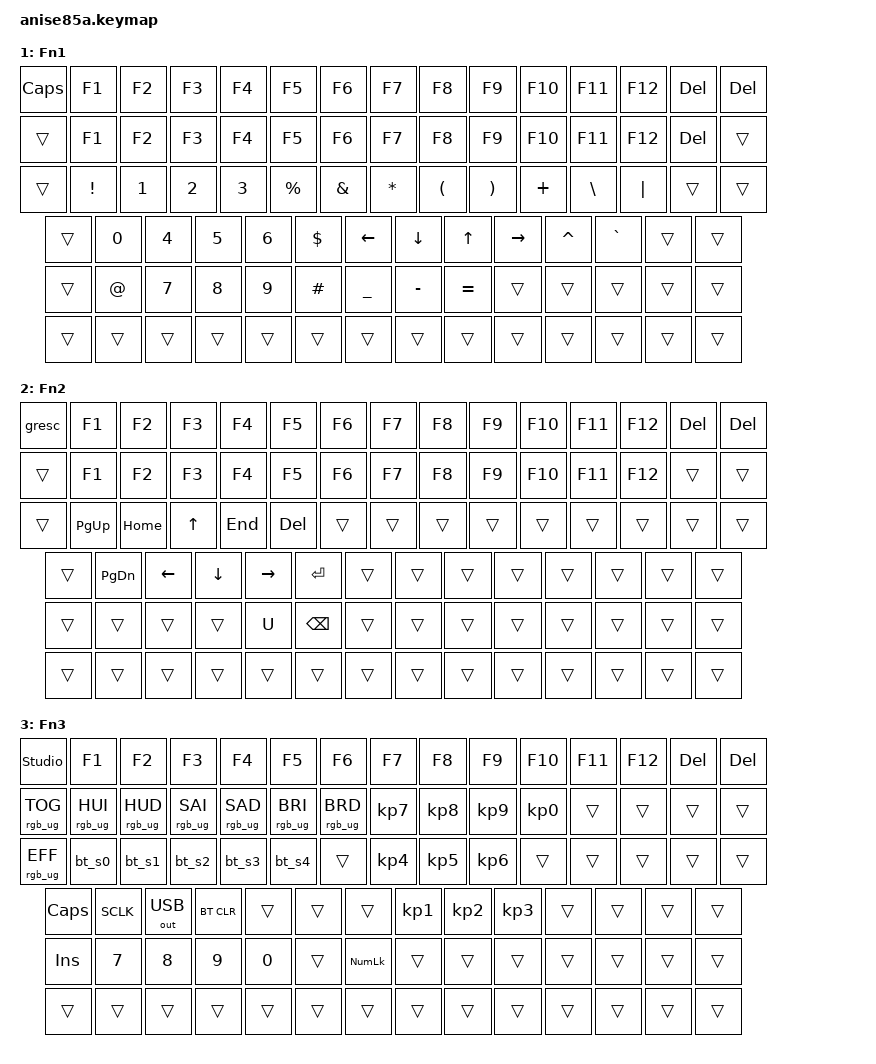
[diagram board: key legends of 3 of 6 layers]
/*
 * Copyright (c) 2020 The ZMK Contributors
 *
 * SPDX-License-Identifier: MIT
 */

#include <behaviors.dtsi>
#include <dt-bindings/zmk/rgb.h>
#include <dt-bindings/zmk/bt.h>
#include <dt-bindings/zmk/outputs.h>
#include <dt-bindings/zmk/keys.h>

/ {
    behaviors {
        gresc: grave_escape {
            compatible = "zmk,behavior-mod-morph";
            label = "GRAVE_ESCAPE";
            #binding-cells = <0>;
            bindings = <&kp ESC>, <&kp GRAVE>;
            mods = <(MOD_LGUI|MOD_LSFT|MOD_RGUI|MOD_RSFT)>;
        };
    };
    macros {
        bt_s0: bt_s0 {
            label = "bt_s0";
            compatible = "zmk,behavior-macro";
            #binding-cells = <0>;
            bindings = <&macro_tap &out OUT_BLE &bt BT_SEL 0>;
        };
        bt_s1: bt_s1 {
            label = "bt_s1";
            compatible = "zmk,behavior-macro";
            #binding-cells = <0>;
            bindings = <&macro_tap &out OUT_BLE &bt BT_SEL 1>;
        };
        bt_s2: bt_s2 {
            label = "bt_s2";
            compatible = "zmk,behavior-macro";
            #binding-cells = <0>;
            bindings = <&macro_tap &out OUT_BLE &bt BT_SEL 2>;
        };
        bt_s3: bt_s3 {
            label = "bt_s3";
            compatible = "zmk,behavior-macro";
            #binding-cells = <0>;
            bindings = <&macro_tap &out OUT_BLE &bt BT_SEL 3>;
        };
        bt_s4: bt_s4 {
            label = "bt_s4";
            compatible = "zmk,behavior-macro";
            #binding-cells = <0>;
            bindings = <&macro_tap &out OUT_BLE &bt BT_SEL 4>;
        };
    };
    keymap {
        compatible = "zmk,keymap";

// -------------------------------------------       ------------------------------------------------------
// | ESC | |  1   |  2  |  3   |  4  | | 5   |       |  6  | | 7 |  8  |  9  | 10  | 11  | 12  |
// | GESC |  1  |  2  |  3  |  4  |  5  |  6 |       |  7  |  8  |  9  |  0  |  -  |  =  |   BKSPC | | HOME  |
// | TAB   |  Q   |  W  |  E   |  R  |  T  |        |  Y  |  U  |  I  |  O  |  P  |  [  |  ]  |  \ | | END   |
// | CAPS   |  A   |  S  |  D   |  F  |  G  |        |  H  |  J  |  K  |  L  |  ;  |  '  |   ENTER | | PGUP  |
// | SHIFT   |  Z   |  X  |  C   |  V   |  B  |       |  N  |  M  |  ,  |  .  |  /   |  RSHFT  || UP|| PGDN  |
// | F | LCTL | LGUI | LALT |    SPACE  | FN2 |       |   SPACE   | FN1  | RALT |  RCTL  | LEFT | DN | RIGHT |
// -------------------------------------------        ------------------------------------------------------

        // 0
        default_layer {
            display-name = "Base";
            bindings = <
    &kp ESC   &kp F1   &kp F2   &kp F3   &kp F4  &kp F5  &kp F6 /**/   &kp F7  &kp F8     &kp F9 &kp F10 &kp F11 &kp F12        &kp DEL                          &kp C_PP
    &kp GRAVE &kp N1   &kp N2   &kp N3   &kp N4   &kp N5  &kp N6 /**/   &kp N7    &kp N8   &kp N9    &kp N0    &kp MINUS &kp EQUAL &kp BSPC                       &kp HOME
    &kp TAB    &kp Q    &kp W    &kp E    &kp R    &kp T        /**/ &kp Y     &kp U    &kp I     &kp O     &kp P     &kp LBKT  &kp RBKT &kp BSPC                &kp END
    &kp ESC      &kp A    &kp S    &kp D    &kp F  &kp G         /**/  &kp H     &kp J    &kp K     &kp L     &kp SEMI  &kp SQT   &kp RET                         &kp PG_UP
    &kp LSHFT     &kp Z    &kp X    &kp C    &kp V  &kp B       /**/    &kp N     &kp M    &kp COMMA &kp DOT   &kp FSLH  &kp RSHFT                   &kp UP      &kp PG_DN
    &kp LCTRL &mo 3 &kp LGUI  &kp LALT  &kp SPACE     &mo 2    /**/ &kp SPACE &mo 1    &mo 4      &mo 5                             &kp LEFT        &kp DOWN   &kp RIGHT 
            >;
        };
        // 1
        fn_layer {
            display-name = "Fn1";
            bindings = <
    &kp CAPS  &kp F1   &kp F2   &kp F3   &kp F4  &kp F5  &kp F6 /**/   &kp F7  &kp F8     &kp F9 &kp F10 &kp F11 &kp F12        &kp DEL                          &kp DEL
    &trans     &kp F1     &kp F2   &kp F3    &kp F4   &kp F5    &kp F6   /**/   &kp F7   &kp F8   &kp F9   &kp F10   &kp F11 &kp F12     &kp DEL                        &trans
    &trans      &kp EXCL   &kp N1   &kp N2    &kp N3   &kp PRCNT         /**/ &kp AMPS  &kp STAR &kp LPAR &kp RPAR  &kp PLUS  &kp BSLH  &kp PIPE  &trans                &trans
    &trans       &kp N0     &kp N4   &kp N5    &kp N6   &kp DLLR         /**/  &kp LEFT  &kp DOWN &kp UP   &kp RIGHT &kp CARET  &kp GRAVE  &trans                       &trans
    &trans         &kp AT     &kp N7   &kp N8    &kp N9   &kp HASH       /**/    &kp UNDER &kp MINUS &kp EQUAL &trans  &trans  &trans                         &trans    &trans
    &trans  &trans    &trans      &trans             &trans      &trans  /**/    &trans        &trans &trans &trans  &trans                         &trans    &trans   &trans
            >;
        };
        // 2
        fn2_layer {
            display-name = "Fn2";
            bindings = <
    &gresc    &kp F1   &kp F2   &kp F3   &kp F4  &kp F5  &kp F6 /**/   &kp F7  &kp F8     &kp F9 &kp F10 &kp F11 &kp F12        &kp DEL                          &kp DEL
    &trans     &kp F1       &kp F2       &kp F3       &kp F4    &kp F5    &kp F6   /**/   &kp F7    &kp F8    &kp F9    &kp F10    &kp F11 &kp F12 &trans               &trans
    &trans      &kp PG_UP &kp HOME   &kp UP      &kp END      &kp DEL              /**/ &trans &trans    &trans    &trans     &trans  &trans  &trans &trans             &trans
    &trans        &kp PG_DN  &kp LEFT     &kp DOWN     &kp RIGHT &kp RET         /**/  &trans &trans    &trans    &trans     &trans  &trans  &trans                     &trans
    &trans           &trans       &trans      &trans       &kp U      &kp BSPC     /**/     &trans     &trans &trans &trans  &trans  &trans                   &trans    &trans
    &trans  &trans    &trans      &trans             &trans      &trans  /**/    &trans        &trans &trans &trans  &trans                         &trans    &trans   &trans
            >;
        };
        // 3
        kbd_func_layer {
            display-name = "Fn3";
            bindings = <
    &studio_unlock  &kp F1   &kp F2   &kp F3   &kp F4  &kp F5  &kp F6 /**/   &kp F7  &kp F8     &kp F9 &kp F10 &kp F11 &kp F12        &kp DEL                          &kp DEL
    &rgb_ug RGB_TOG &rgb_ug RGB_HUI  &rgb_ug RGB_HUD &rgb_ug RGB_SAI &rgb_ug RGB_SAD &rgb_ug RGB_BRI &rgb_ug RGB_BRD  /**/   &kp KP_N7 &kp KP_N8 &kp KP_N9 &kp KP_N0  &trans  &trans  &trans                     &trans
    &rgb_ug RGB_EFF &bt_s0   &bt_s1     &bt_s2       &bt_s3       &bt_s4                                              /**/ &trans &kp KP_N4 &kp KP_N5 &kp KP_N6  &trans  &trans  &trans &trans                   &trans
    &kp CAPS      &kp SCLK      &out OUT_USB &bt BT_CLR   &trans    &trans                                            /**/  &trans &kp KP_N1 &kp KP_N2 &kp KP_N3  &trans  &trans  &trans                         &trans
    &kp INS        &kp N7         &kp N8      &kp N9       &kp N0     &trans                                          /**/     &kp KP_NUM &trans &trans &trans  &trans  &trans                         &trans    &trans
    &trans  &trans    &trans      &trans             &trans      &trans                                               /**/    &trans        &trans &trans &trans  &trans                     &trans    &trans   &trans
            >;
        };
        // 4 -- keyd [sym], held on right Alt
        sym_layer {
            display-name = "Sym";
            bindings = <
    &trans &trans &trans &trans &trans &trans &trans &trans &trans &trans &trans &trans &trans &trans &trans
    &trans &trans &trans &trans &trans &trans &trans &trans &trans &trans &trans &trans &trans &trans &trans
    &kp EQUAL  &kp EXCL &kp N1   &kp N2   &kp N3   &kp PRCNT    /**/ &kp AMPS  &kp STAR &kp LPAR  &kp RPAR  &kp PLUS  &kp BSLH  &kp PIPE &kp DEL                 &trans
    &kp CAPS     &kp N0   &kp N4   &kp N5   &kp N6 &kp DLLR     /**/  &kp LEFT  &kp DOWN &kp UP    &kp RIGHT &kp CARET &kp GRAVE &trans                          &trans
    &trans        &kp AT   &kp N7   &kp N8   &kp N9 &kp HASH    /**/    &kp MINUS &kp HOME &kp PG_UP &kp PG_DN &kp END   &trans                      &trans      &trans
    &trans &trans &trans &trans &trans &trans &trans &trans &trans &trans &trans &trans &trans
            >;
        };
        // 5 -- keyd [fn], held on right Ctrl
        fkey_layer {
            display-name = "FKeys";
            bindings = <
    &trans &trans &trans &trans &trans &trans &trans &trans &trans &trans &trans &trans &trans &trans &trans
    &trans &trans &trans &trans &trans &trans &trans &trans &trans &trans &trans &trans &trans &trans &trans
    &trans     &trans   &kp F1   &kp F2   &kp F3   &trans       /**/ &trans    &trans   &trans    &trans    &trans    &kp F11   &kp F12  &trans                  &trans
    &trans       &kp F10  &kp F4   &kp F5   &kp F6 &trans       /**/  &trans    &trans   &trans    &trans    &trans    &trans    &trans                          &trans
    &trans        &trans   &kp F7   &kp F8   &kp F9 &trans      /**/    &trans    &trans   &trans    &trans    &trans    &trans                      &trans      &trans
    &trans &trans &trans &trans &trans &trans &trans &trans &trans &trans &trans &trans &trans
            >;
        };
    };
};

    // &trans          &trans           &trans          &trans          &trans          &trans          &trans           /**/   &kp KP_N7 &kp KP_N8 &kp KP_N9 &kp KP_N0  &trans  &trans  &trans                     &trans
//         // 0
//         default_layer {
//             bindings = <
//     &gresc   &kp N1   &kp N2   &kp N3   &kp N4   &kp N5  &kp N6 /**/   &kp N7    &kp N8   &kp N9    &kp N0    &kp MINUS &kp EQUAL &kp BSPC
//     &kp TAB    &kp Q    &kp W    &kp E    &kp R    &kp T        /**/ &kp Y     &kp U    &kp I     &kp O     &kp P     &kp LBKT  &kp RBKT &kp BSPC
//     &kp ESC     &kp A    &kp S    &kp D    &kp F  &kp G         /**/  &kp H     &kp J    &kp K     &kp L     &kp SEMI  &kp SQT   &kp RET
//     &kp LSHFT     &kp Z    &kp X    &kp C    &kp V  &kp B       /**/    &kp N     &kp M    &kp COMMA &kp DOT   &kp FSLH  &kp RSHFT
//     &kp LALT    &kp LGUI  &kp LCTRL      &kp SPACE     &mo 2    /**/ &kp SPACE &mo 1    &kp RALT  &kp K_APP  &kp RCTRL
//             >;
//         };
//         // 1
//         fn_layer {
//             bindings = <
//     &trans     &kp F1     &kp F2   &kp F3    &kp F4   &kp F5    &kp F6   /**/   &kp F7   &kp F8   &kp F9   &kp F10   &kp F11 &kp F12     &kp DEL
//     &trans      &kp EXCL   &kp N1   &kp N2    &kp N3   &kp PRCNT         /**/ &kp AMPS  &kp STAR &kp LPAR &kp RPAR  &kp PLUS  &kp BSLH  &kp PIPE  &trans
//     &trans       &kp N0     &kp N4   &kp N5    &kp N6   &kp DLLR         /**/  &kp LEFT  &kp DOWN &kp UP   &kp RIGHT &kp CARET  &kp GRAVE  &trans
//     &trans         &kp AT     &kp N7   &kp N8    &kp N9   &kp HASH       /**/    &kp UNDER &kp MINUS &kp EQUAL &trans  &trans  &kp PG_UP
//     &trans            &trans      &trans             &trans      &trans  /**/    &trans        &trans &trans &trans  &kp PG_DN
//             >;
//         };

//         // 0
//         default_layer {
//             bindings = <
//     &gresc   &kp N1   &kp N2   &kp N3   &kp N4   &kp N5  &kp N6 /**/   &kp N7    &kp N8   &kp N9    &kp N0    &kp MINUS &kp EQUAL &kp BSPC
//     &kp TAB    &kp Q    &kp W    &kp E    &kp R    &kp T        /**/ &kp Y     &kp U    &kp I     &kp O     &kp P     &kp LBKT  &kp RBKT &kp BSLH
//     &kp CAPS     &kp A    &kp S    &kp D    &kp F  &kp G        /**/  &kp H     &kp J    &kp K     &kp L     &kp SEMI  &kp SQT   &kp RET
//     &kp LSHFT     &kp Z    &kp X    &kp C    &kp V  &kp B       /**/    &kp N     &kp M    &kp COMMA &kp DOT   &kp FSLH  &kp RSHFT
//     &kp LCTRL    &kp LGUI  &kp LALT      &kp SPACE     &mo 2    /**/ &kp SPACE &mo 1    &kp RALT  &kp K_APP  &kp RCTRL
//             >;
//         };
//         // 1
//         fn_layer {
//             bindings = <
//     &trans     &kp F1     &kp F2   &kp F3    &kp F4   &kp F5    &kp F6   /**/   &kp F7   &kp F8   &kp F9   &kp F10   &kp F11 &kp F12     &kp DEL
//     &trans      &trans     &kp N1   &kp N2    &kp N3   &trans            /**/ &trans    &trans   &kp UP   &trans    &trans    &trans    &trans    &trans
//     &trans       &kp N0     &kp N4   &kp N5    &kp N6   &trans           /**/  &trans    &kp LEFT &kp DOWN &kp RIGHT &trans     &kp GRAVE  &trans
//     &trans         &trans     &kp N7   &kp N8    &kp N9   &trans         /**/    &trans    &trans    &trans    &trans  &trans  &kp PG_UP
//     &trans            &trans      &trans             &trans      &trans  /**/    &trans        &trans &trans &trans  &kp PG_DN
//             >;
//         };
